AUTOSAR XML (schema 00051)
package /ComponentTypes
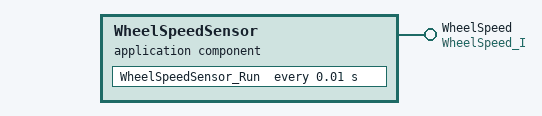
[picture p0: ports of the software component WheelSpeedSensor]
  application sw component type WheelSpeedSensor
    provide port WheelSpeed: nonqueued-sender-com-spec{data-element=WheelSpeed, init-value=constant-reference=WheelSpeed_IV}, provided-interface=WheelSpeed_I
    behavior WheelSpeedSensor_InternalBehavior: port-api-option{enable-take-address=false, indirect-api=false, port=WheelSpeed}
      timing event TMT_WheelSpeedSensor_Run: start-on-event=WheelSpeedSensor_Run, period=0.01
      runnable WheelSpeedSensor_Run
        data-send-points:
          access SEND_WheelSpeed_WheelSpeed: accessed-variable=WheelSpeed.WheelSpeed
  swc implementation WheelSpeedSensor_Implementation: behavior=WheelSpeedSensor_InternalBehavior
